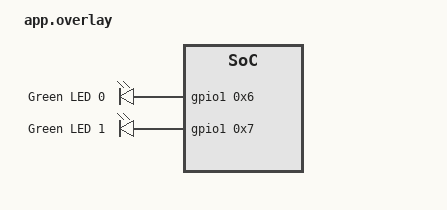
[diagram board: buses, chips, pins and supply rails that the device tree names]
/{
    leds {
        compatible = "gpio-leds";
        led0: led_0 {
            gpios = < &gpio1 0x6 0x0 >;
            label = "Green LED 0";
        };
        led1: led_1 {
            gpios = < &gpio1 0x7 0x0 >;
            label = "Green LED 1";
        };
    };

};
